AUTOSAR XML (schema 4-2-2)
package /BMSL_FlatView/SwComponentTypes
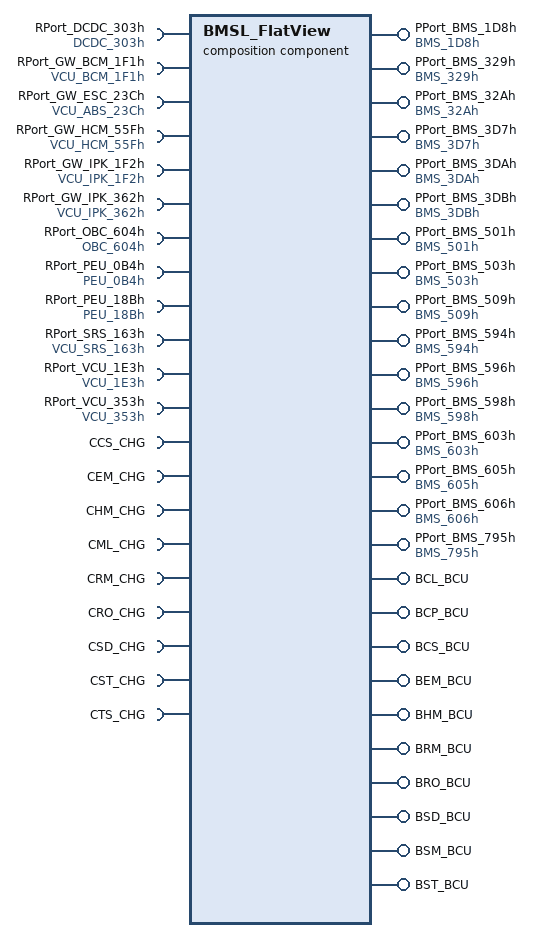
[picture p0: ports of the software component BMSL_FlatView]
  composition sw component type BMSL_FlatView
    16 x provide port:
      PPort_BMS_1D8h: provided-interface=BMS_1D8h
      PPort_BMS_329h: provided-interface=BMS_329h
      PPort_BMS_32Ah: provided-interface=BMS_32Ah
      PPort_BMS_3D7h: provided-interface=BMS_3D7h
      PPort_BMS_3DAh: provided-interface=BMS_3DAh
      PPort_BMS_3DBh: provided-interface=BMS_3DBh
      PPort_BMS_501h: provided-interface=BMS_501h
      PPort_BMS_503h: provided-interface=BMS_503h
      PPort_BMS_509h: provided-interface=BMS_509h
      PPort_BMS_594h: provided-interface=BMS_594h
      PPort_BMS_596h: provided-interface=BMS_596h
      PPort_BMS_598h: provided-interface=BMS_598h
      PPort_BMS_603h: provided-interface=BMS_603h
      PPort_BMS_605h: provided-interface=BMS_605h
      PPort_BMS_606h: provided-interface=BMS_606h
      PPort_BMS_795h: provided-interface=BMS_795h
    12 x require port:
      RPort_DCDC_303h: required-interface=DCDC_303h
      RPort_GW_BCM_1F1h: required-interface=VCU_BCM_1F1h
      RPort_GW_ESC_23Ch: required-interface=VCU_ABS_23Ch
      RPort_GW_HCM_55Fh: required-interface=VCU_HCM_55Fh
      RPort_GW_IPK_1F2h: required-interface=VCU_IPK_1F2h
      RPort_GW_IPK_362h: required-interface=VCU_IPK_362h
      RPort_OBC_604h: required-interface=OBC_604h
      RPort_PEU_0B4h: required-interface=PEU_0B4h
      RPort_PEU_18Bh: required-interface=PEU_18Bh
      RPort_SRS_163h: required-interface=VCU_SRS_163h
      RPort_VCU_1E3h: required-interface=VCU_1E3h
      RPort_VCU_353h: required-interface=VCU_353h
    10 x provide port:
      BCL_BCU: provided-interface=BCL_BCU
      BCP_BCU: provided-interface=BCP_BCU
      BCS_BCU: provided-interface=BCS_BCU
      BEM_BCU: provided-interface=BEM_BCU
      BHM_BCU: provided-interface=BHM_BCU
      BRM_BCU: provided-interface=BRM_BCU
      BRO_BCU: provided-interface=BRO_BCU
      BSD_BCU: provided-interface=BSD_BCU
      BSM_BCU: provided-interface=BSM_BCU
      BST_BCU: provided-interface=BST_BCU
    9 x require port:
      CCS_CHG: required-interface=CCS_CHG
      CEM_CHG: required-interface=CEM_CHG
      CHM_CHG: required-interface=CHM_CHG
      CML_CHG: required-interface=CML_CHG
      CRM_CHG: required-interface=CRM_CHG
      CRO_CHG: required-interface=CRO_CHG
      CSD_CHG: required-interface=CSD_CHG
      CST_CHG: required-interface=CST_CHG
      CTS_CHG: required-interface=CTS_CHG
    12 x component:
      CPT_Asw_Swc: type=Asw_Swc
      CPT_BswM: type=BswM
      CPT_Cmu_Cdd: type=Cmu_Cdd
      CPT_ComM: type=ComM
      CPT_Det: type=Det
      CPT_EcuM: type=EcuM
      CPT_IoHwAb: type=IoHwAb
      CPT_NvM: type=NvM
      CPT_Sbc_Cdd: type=Sbc_Cdd
      CPT_WdgM: type=WdgM
      CPT_WdgM_SWC: type=WdgM_SWC
      CPT_Xcp_SWC: type=Xcp_SWC
    connect CPT_Asw_Swc.PPort_BswMArbitration_BswM_MRP_SwcModeRequest -> CPT_BswM.RP_BswMArbitration_BswM_MRP_SwcModeRequest
    connect CPT_Asw_Swc.CmuCmd -> CPT_Cmu_Cdd.CmuCmd
    connect CPT_Asw_Swc.FblCmd -> CPT_IoHwAb.FblCmd
    connect CPT_Asw_Swc.PPort_NVDataBlock1_Finished -> CPT_NvM.NVDataBlock1_Finished
    connect CPT_Asw_Swc.RelayCmd -> CPT_IoHwAb.RelayCmd
    connect CPT_Cmu_Cdd.CmuValue -> CPT_Asw_Swc.CmuValue
    connect CPT_EcuM.shutdownTarget -> CPT_Asw_Swc.RPort_EcuM_ShutdownTarget
    connect CPT_IoHwAb.McuValue -> CPT_Asw_Swc.McuValue
    connect CPT_IoHwAb.PowerValue -> CPT_Asw_Swc.PowerValue
    connect CPT_IoHwAb.RelayValue -> CPT_Asw_Swc.RelayValue
    connect CPT_NvM.NVDataBlock1 -> CPT_Asw_Swc.RPort_NVDataBlock1
    connect CPT_Sbc_Cdd.SbcValue -> CPT_Asw_Swc.SbcValue
    connect CPT_WdgM.alive_WdgMAliveSupervisedEntity_Asw_5ms -> CPT_WdgM_SWC.RPort_AliveSupervision_Asw_5ms
    connect CPT_WdgM.alive_WdgMAliveSupervisedEntity_Bsw_1000ms -> CPT_WdgM_SWC.RPort_AliveSupervision_Bsw_1000ms
    connect CPT_WdgM.alive_WdgMAliveSupervisedEntity_Bsw_100ms -> CPT_WdgM_SWC.RPort_AliveSupervision_Bsw_100ms
    connect CPT_WdgM.alive_WdgMAliveSupervisedEntity_Bsw_10ms -> CPT_WdgM_SWC.RPort_AliveSupervision_Bsw_10ms
    connect CPT_WdgM.alive_WdgMAliveSupervisedEntity_Bsw_20ms -> CPT_WdgM_SWC.RPort_AliveSupervision_Bsw_20ms
    connect CPT_WdgM.alive_WdgMAliveSupervisedEntity_Bsw_50ms -> CPT_WdgM_SWC.RPort_AliveSupervision_Bsw_50ms
    connect CPT_WdgM.alive_WdgMAliveSupervisedEntity_Bsw_5ms -> CPT_WdgM_SWC.RPort_AliveSupervision_Bsw_5ms
    connect CPT_ComM.UR_ComMUser_Can_Network_0_Channel -> CPT_Asw_Swc.RPort_ComM_UserRequest
    connect CPT_IoHwAb.ChargeValue -> CPT_Asw_Swc.ChargeValue
    connect CPT_IoHwAb.HighVoltValue -> CPT_Asw_Swc.HighVoltValue
    connect CPT_IoHwAb.IsoValue -> CPT_Asw_Swc.IsoValue
    connect CPT_IoHwAb.SbcValue -> CPT_Asw_Swc.SbcValue
    connect CPT_IoHwAb.CrashValue -> CPT_Asw_Swc.CrashValue
    connect CPT_IoHwAb.CurrValue -> CPT_Asw_Swc.CurrValue
    connect CPT_IoHwAb.HvilValue -> CPT_Asw_Swc.HvilValue
    connect CPT_IoHwAb.RsvValue -> CPT_Asw_Swc.RsvValue
    connect CPT_IoHwAb.ThermalValue -> CPT_Asw_Swc.ThermalValue
    connect CPT_Asw_Swc.ChargeCmd -> CPT_IoHwAb.ChargeCmd
    connect CPT_Asw_Swc.HvilCmd -> CPT_IoHwAb.HvilCmd
    connect CPT_Asw_Swc.IsoCmd -> CPT_IoHwAb.IsoCmd
    connect CPT_Asw_Swc.McuCmd -> CPT_IoHwAb.McuCmd
    connect CPT_Asw_Swc.ThermalCmd -> CPT_IoHwAb.ThermalCmd
    delegate CPT_Asw_Swc.BMS_1D8h <-> outer port PPort_BMS_1D8h
    delegate CPT_Asw_Swc.BMS_329h <-> outer port PPort_BMS_329h
    delegate CPT_Asw_Swc.BMS_32Ah <-> outer port PPort_BMS_32Ah
    delegate CPT_Asw_Swc.BMS_3D7h <-> outer port PPort_BMS_3D7h
    delegate CPT_Asw_Swc.BMS_3DAh <-> outer port PPort_BMS_3DAh
    delegate CPT_Asw_Swc.BMS_3DBh <-> outer port PPort_BMS_3DBh
    delegate CPT_Asw_Swc.BMS_501h <-> outer port PPort_BMS_501h
    delegate CPT_Asw_Swc.BMS_503h <-> outer port PPort_BMS_503h
    delegate CPT_Asw_Swc.BMS_509h <-> outer port PPort_BMS_509h
    delegate CPT_Asw_Swc.BMS_594h <-> outer port PPort_BMS_594h
    delegate CPT_Asw_Swc.BMS_596h <-> outer port PPort_BMS_596h
    delegate CPT_Asw_Swc.BMS_598h <-> outer port PPort_BMS_598h
    delegate CPT_Asw_Swc.BMS_603h <-> outer port PPort_BMS_603h
    delegate CPT_Asw_Swc.BMS_605h <-> outer port PPort_BMS_605h
    delegate CPT_Asw_Swc.BMS_606h <-> outer port PPort_BMS_606h
    delegate CPT_Asw_Swc.BMS_795h <-> outer port PPort_BMS_795h
    connect CPT_Asw_Swc.HighVoltCmd -> CPT_IoHwAb.HighVoltCmd
    connect CPT_IoHwAb.Rtc -> CPT_Asw_Swc.Rtc
    connect CPT_Cmu_Cdd.Cmu -> CPT_Asw_Swc.Cmu
    delegate CPT_Asw_Swc.DCDC_303h <-> outer port RPort_DCDC_303h
    delegate CPT_Asw_Swc.VCU_BCM_1F1h <-> outer port RPort_GW_BCM_1F1h
    delegate CPT_Asw_Swc.VCU_ABS_23Ch <-> outer port RPort_GW_ESC_23Ch
    delegate CPT_Asw_Swc.VCU_HCM_55Fh <-> outer port RPort_GW_HCM_55Fh
    delegate CPT_Asw_Swc.VCU_IPK_1F2h <-> outer port RPort_GW_IPK_1F2h
    delegate CPT_Asw_Swc.VCU_IPK_362h <-> outer port RPort_GW_IPK_362h
    delegate CPT_Asw_Swc.OBC_604h <-> outer port RPort_OBC_604h
    delegate CPT_Asw_Swc.PEU_0B4h <-> outer port RPort_PEU_0B4h
    delegate CPT_Asw_Swc.PEU_18Bh <-> outer port RPort_PEU_18Bh
    delegate CPT_Asw_Swc.VCU_SRS_163h <-> outer port RPort_SRS_163h
    delegate CPT_Asw_Swc.VCU_1E3h <-> outer port RPort_VCU_1E3h
    delegate CPT_Asw_Swc.VCU_353h <-> outer port RPort_VCU_353h
    delegate CPT_Asw_Swc.BCL_BCU <-> outer port BCL_BCU
    delegate CPT_Asw_Swc.BCP_BCU <-> outer port BCP_BCU
    delegate CPT_Asw_Swc.BCS_BCU <-> outer port BCS_BCU
    delegate CPT_Asw_Swc.BEM_BCU <-> outer port BEM_BCU
    delegate CPT_Asw_Swc.BHM_BCU <-> outer port BHM_BCU
    delegate CPT_Asw_Swc.BRM_BCU <-> outer port BRM_BCU
    delegate CPT_Asw_Swc.BRO_BCU <-> outer port BRO_BCU
    delegate CPT_Asw_Swc.BSD_BCU <-> outer port BSD_BCU
    delegate CPT_Asw_Swc.BSM_BCU <-> outer port BSM_BCU
    delegate CPT_Asw_Swc.BST_BCU <-> outer port BST_BCU
    delegate CPT_Asw_Swc.CCS_CHG <-> outer port CCS_CHG
    delegate CPT_Asw_Swc.CEM_CHG <-> outer port CEM_CHG
    delegate CPT_Asw_Swc.CHM_CHG <-> outer port CHM_CHG
    delegate CPT_Asw_Swc.CML_CHG <-> outer port CML_CHG
    delegate CPT_Asw_Swc.CRM_CHG <-> outer port CRM_CHG
    delegate CPT_Asw_Swc.CRO_CHG <-> outer port CRO_CHG
    delegate CPT_Asw_Swc.CSD_CHG <-> outer port CSD_CHG
    delegate CPT_Asw_Swc.CST_CHG <-> outer port CST_CHG
    delegate CPT_Asw_Swc.CTS_CHG <-> outer port CTS_CHG
